# R7FA6T2BD register map
Vendor: Renesas Electronics Corporation; Series: RA6; File version: 1.40.00
CPU: CM33 r0p4, little endian, MPU, FPU, VTOR, 4 interrupt priority bits, 96 interrupts
Registers are 32-bit, read-write, reset 0x0 unless marked. A register's access mark holds for its fields unless they carry their own. Offsets are from the block's base; [hi:lo] are bit positions; {n}, {i} and the like mark numbered series; 'fields as' and 'values as' point back to an identical list.

## CANFD — CANFD Module Control
Base 0x400B0000
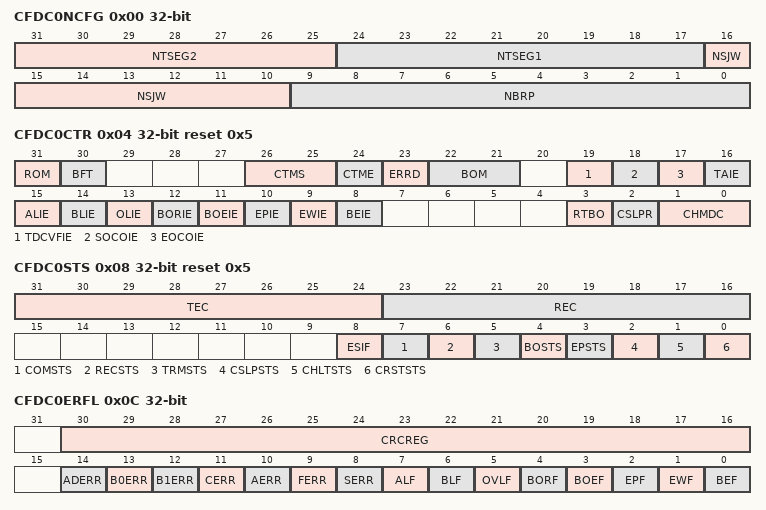
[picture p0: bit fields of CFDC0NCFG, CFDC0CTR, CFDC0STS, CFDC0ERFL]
0x00 CFDC0NCFG — Channel 0 Nominal Bitrate Configuration Register
  [31:25] NTSEG2 — Timing Segment 2
  [24:17] NTSEG1 — Timing Segment 1
  [16:10] NSJW — Resynchronization Jump Width
  [9:0] NBRP — Channel Nominal Baud Rate Prescaler
0x04 CFDC0CTR reset 0x5 — Channel 0 Control Register
  [31] ROM — Restricted Operation Mode
  [30] BFT — Bit Flip Test
  [26:25] CTMS — Channel Test Mode Select
  [24] CTME — Channel Test Mode Enable
  [23] ERRD — Channel Error Display
  [22:21] BOM — Channel Bus,Off Mode
  [19] TDCVFIE — Transceiver Delay Compensation Violation Interrupt Enable
  [18] SOCOIE — Successful Occurrence Counter Overflow Interrupt Enable
  [17] EOCOIE — Error Occurrence Counter Overflow Interrupt Enable
  [16] TAIE — Transmission Abort Interrupt Enable
  [15] ALIE — Arbitration Lost Interrupt Enable
  [14] BLIE — Bus Lock Interrupt Enable
  [13] OLIE — Overload Interrupt Enable
  [12] BORIE — Bus,Off Recovery Interrupt Enable
  [11] BOEIE — Bus,Off Entry Interrupt Enable
  [10] EPIE — Error Passive Interrupt Enable
  [9] EWIE — Error Warning Interrupt Enable
  [8] BEIE — Bus Error Interrupt Enable
  [3] RTBO — Return from Bus,Off
  [2] CSLPR — Channel Sleep Request
  [1:0] CHMDC — Channel Mode Control
0x08 CFDC0STS reset 0x5 — Channel 0 Status Register
  [31:24] TEC ro — Transmission Error Count
  [23:16] REC ro — Reception Error Count
  [8] ESIF — Error State Indication Flag
  [7] COMSTS ro — Channel Communication Status
  [6] RECSTS ro — Channel Receive Status
  [5] TRMSTS ro — Channel Transmit Status
  [4] BOSTS ro — Channel Bus,Off Status
  [3] EPSTS ro — Channel Error Passive Status
  [2] CSLPSTS ro — Channel Sleep Status
  [1] CHLTSTS ro — Channel Halt Status
  [0] CRSTSTS ro — Channel Reset Status
0x0C CFDC0ERFL — Channel 0 Error Flag Register
  [30:16] CRCREG ro — CRC Register value
  [14] ADERR — Acknowledge Delimiter Error
  [13] B0ERR — Bit 0 Error
  [12] B1ERR — Bit 1 Error
  [11] CERR — CRC Error
  [10] AERR — Acknowledge Error
  [9] FERR — Form Error
  [8] SERR — Stuff Error
  [7] ALF — Arbitration Lost Flag
  [6] BLF — Bus Lock Flag
  [5] OVLF — Overload Flag
  [4] BORF — Bus,Off Recovery Flag
  [3] BOEF — Bus,Off Entry Flag
  [2] EPF — Error Passive Flag
  [1] EWF — Error Warning Flag
  [0] BEF — Bus Error Flag
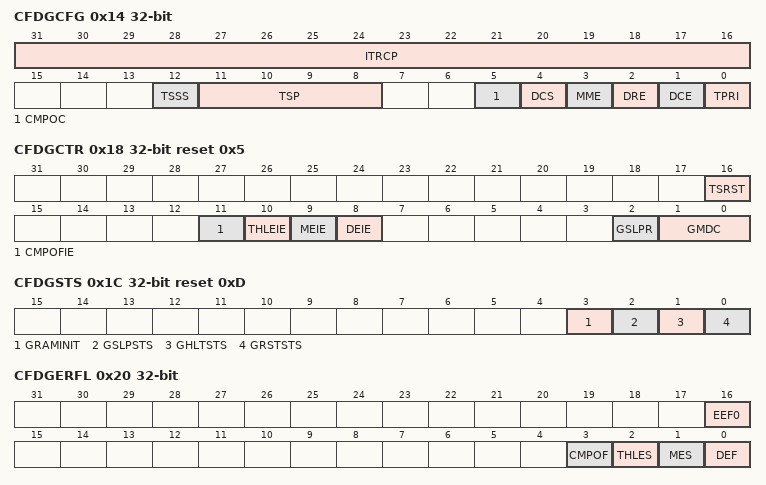
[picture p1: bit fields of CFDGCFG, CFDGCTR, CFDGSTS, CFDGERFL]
0x14 CFDGCFG — Global Configuration Register
  [31:16] ITRCP — Interval Timer Reference Clock Prescaler
  [12] TSSS — Timestamp Source Select
  [11:8] TSP — Timestamp Prescaler
  [5] CMPOC — CANFD Message Payload Overflow Configuration
  [4] DCS — Data Link Controller Clock Select
  [3] MME — Mirror Mode Enable
  [2] DRE — DLC Replacement Enable
  [1] DCE — DLC Check Enable
  [0] TPRI — Transmission Priority
0x18 CFDGCTR reset 0x5 — Global Control Register
  [16] TSRST — Timestamp Reset
  [11] CMPOFIE — CANFD Message Payload Overflow Flag Interrupt Enable
  [10] THLEIE — TX History List Entry Lost Interrupt Enable
  [9] MEIE — Message Lost Error Interrupt Enable
  [8] DEIE — DLC Check Interrupt Enable
  [2] GSLPR — Global Sleep Request
  [1:0] GMDC — Global Mode Control
0x1C CFDGSTS ro reset 0xD — Global Status Register
  [3] GRAMINIT — Global RAM Initialization
  [2] GSLPSTS — Global Sleep Status
  [1] GHLTSTS — Global Halt Status
  [0] GRSTSTS — Global Reset Status
0x20 CFDGERFL — Global Error Flag Register
  [16] EEF0 — ECC Error Flag
  [3] CMPOF — CANFD Message Payload Overflow Flag
  [2] THLES ro — TX History List Entry Lost Error Status
  [1] MES ro — Message Lost Error Status
  [0] DEF — DLC Error Flag
0x24 CFDGTSC ro — Global Timestamp Counter Register
  [15:0] TS — Timestamp value
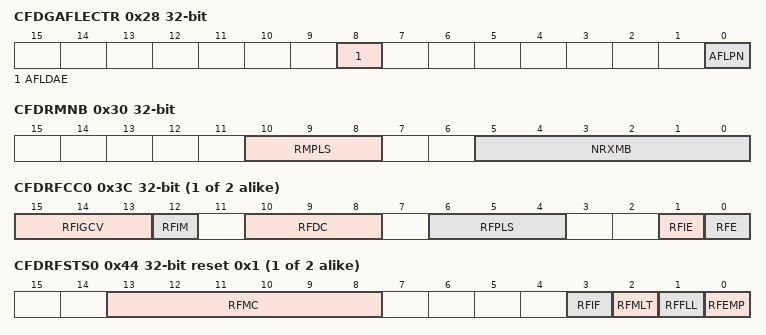
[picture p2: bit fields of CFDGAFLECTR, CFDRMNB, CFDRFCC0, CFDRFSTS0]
0x28 CFDGAFLECTR — Global Acceptance Filter List Entry Control Register
  [8] AFLDAE — Acceptance Filter List Data Access Enable
  [0] AFLPN — Acceptance Filter List Page Number
0x2C CFDGAFLCFG — Global Acceptance Filter List Configuration Register
  [21:16] RNC0 — Rule Number
0x30 CFDRMNB — RX Message Buffer Number Register
  [10:8] RMPLS — Reception Message Buffer Payload Data Size
  [5:0] NRXMB — Number of RX Message Buffers
0x34 CFDRMND — RX Message Buffer New Data Register
  [31:0] RMNS — RX Message Buffer New Data Status
0x38 CFDRMIEC — RX Message Buffer Interrupt Enable Configuration Register
  [31:0] RMIEg — RX Message Buffer Interrupt Enable
{0x3C+4i} CFDRFCC{i} (i=0..1) — RX FIFO Configuration/Control Registers {i}
  [15:13] RFIGCV — RX FIFO Interrupt Generation Counter Value
  [12] RFIM — RX FIFO Interrupt Mode
  [10:8] RFDC — RX FIFO Depth Configuration
  [6:4] RFPLS — Rx FIFO Payload Data Size Configuration
  [1] RFIE — RX FIFO Interrupt Enable
  [0] RFE — RX FIFO Enable
{0x44+4i} CFDRFSTS{i} (i=0..1) reset 0x1 — RX FIFO Status Registers {i}
  [13:8] RFMC ro — RX FIFO Message Count
  [3] RFIF — RX FIFO Interrupt Flag
  [2] RFMLT — RX FIFO Message Lost
  [1] RFFLL ro — RX FIFO Full
  [0] RFEMP ro — RX FIFO Empty
{0x4C+4i} CFDRFPCTR{i} (i=0..1) wo — RX FIFO Pointer Control Registers {i}
  [7:0] RFPC — RX FIFO Pointer Control
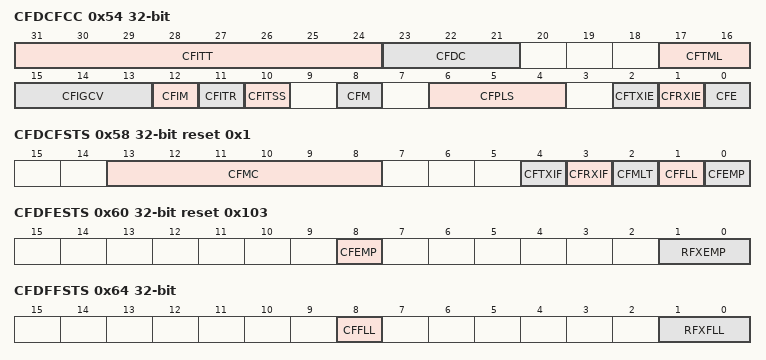
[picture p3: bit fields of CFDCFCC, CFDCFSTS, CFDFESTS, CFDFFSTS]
0x54 CFDCFCC — Common FIFO Configuration/Control Register
  [31:24] CFITT — Common FIFO Interval Transmission Time
  [23:21] CFDC — Common FIFO Depth Configuration
  [17:16] CFTML — Common FIFO TX Message Buffer Link
  [15:13] CFIGCV — Common FIFO Interrupt Generation Counter Value
  [12] CFIM — Common FIFO Interrupt Mode
  [11] CFITR — Common FIFO Interval Timer Resolution
  [10] CFITSS — Common FIFO Interval Timer Source Select
  [8] CFM — Common FIFO Mode
  [6:4] CFPLS — Common FIFO Payload Data Size Configuration
  [2] CFTXIE — Common FIFO TX Interrupt Enable
  [1] CFRXIE — Common FIFO RX Interrupt Enable
  [0] CFE — Common FIFO Enable
0x58 CFDCFSTS reset 0x1 — Common FIFO Status Register
  [13:8] CFMC ro — Common FIFO Message Count
  [4] CFTXIF — Common TX FIFO Interrupt Flag
  [3] CFRXIF — Common RX FIFO Interrupt Flag
  [2] CFMLT — Common FIFO Message Lost
  [1] CFFLL ro — Common FIFO Full
  [0] CFEMP ro — Common FIFO Empty
0x5C CFDCFPCTR wo — Common FIFO Pointer Control Register
  [7:0] CFPC — Common FIFO Pointer Control
0x60 CFDFESTS ro reset 0x103 — FIFO Empty Status Register
  [8] CFEMP — Common FIFO Empty Status
  [1:0] RFXEMP — RX FIFO Empty Status
0x64 CFDFFSTS ro — FIFO Full Status Register
  [8] CFFLL — Common FIF0 Full Status
  [1:0] RFXFLL — RX FIF0 Full Status
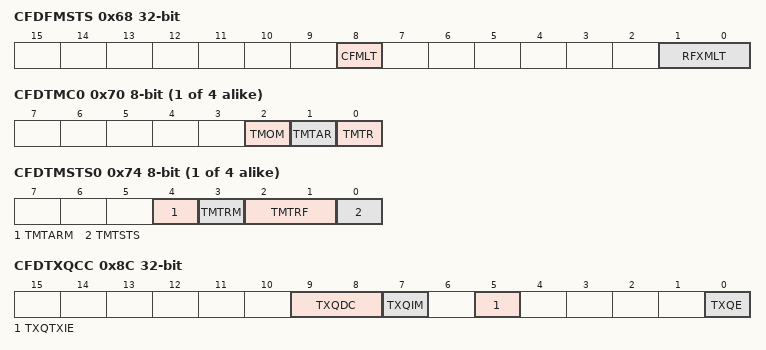
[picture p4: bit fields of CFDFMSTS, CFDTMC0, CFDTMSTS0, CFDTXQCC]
0x68 CFDFMSTS ro — FIFO Message Lost Status Register
  [8] CFMLT — Common FIFO Message Lost Status
  [1:0] RFXMLT — RX FIFO Message Lost Status
0x6C CFDRFISTS ro — RX FIFO Interrupt Flag Status Register
  [1:0] RFXIF — RX FIFO[x] Interrupt Flag Status
{0x70+i} CFDTMC{i} (i=0..3) 8-bit — TX Message Buffer Control Registers {i}
  [2] TMOM — TX Message Buffer One,shot Mode
  [1] TMTAR — TX Message Buffer Transmission Abort Request
  [0] TMTR — TX Message Buffer Transmission Request
{0x74+i} CFDTMSTS{i} (i=0..3) 8-bit — TX Message Buffer Status Registers {i}
  [4] TMTARM ro — TX Message Buffer Transmission Abort Request Mirrored
  [3] TMTRM ro — TX Message Buffer Transmission Request Mirrored
  [2:1] TMTRF — TX Message Buffer Transmission Result Flag
  [0] TMTSTS ro — TX Message Buffer Transmission Status
0x78 CFDTMTRSTS ro — TX Message Buffer Transmission Request Status Register
  [3:0] CFDTMTRSTS — TX Message Buffer Transmission Request Status
0x7C CFDTMTARSTS ro — TX Message Buffer Transmission Abort Request Status Register
  [3:0] CFDTMTARSTS — TX Message Buffer Transmission Abort Request Status
0x80 CFDTMTCSTS ro — TX Message Buffer Transmission Completion Status Register
  [3:0] CFDTMTCSTS — TX Message Buffer Transmission Completion Status
0x84 CFDTMTASTS ro — TX Message Buffer Transmission Abort Status Register
  [3:0] CFDTMTASTS — TX Message Buffer Transmission Abort Status
0x88 CFDTMIEC — TX Message Buffer Interrupt Enable Configuration Register
  [3:0] TMIEg — TX Message Buffer Interrupt Enable
0x8C CFDTXQCC — TX Queue Configuration/Control Register
  [9:8] TXQDC — TX Queue Depth Configuration
  [7] TXQIM — TX Queue Interrupt Mode
  [5] TXQTXIE — TX Queue TX Interrupt Enable
  [0] TXQE — TX Queue Enable
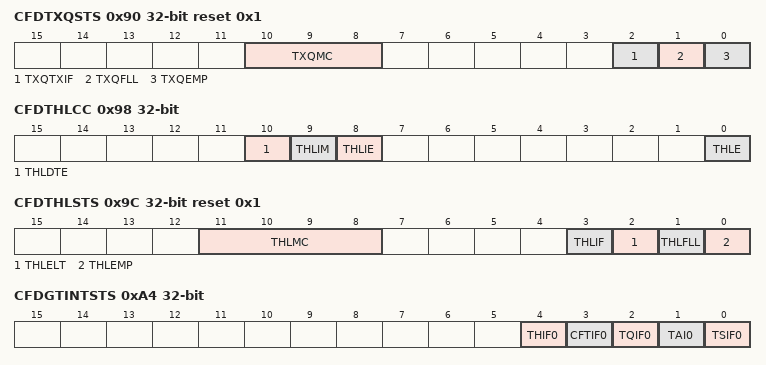
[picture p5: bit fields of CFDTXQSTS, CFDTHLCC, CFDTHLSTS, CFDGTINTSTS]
0x90 CFDTXQSTS reset 0x1 — TX Queue Status Register
  [10:8] TXQMC ro — TX Queue Message Count
  [2] TXQTXIF — TX Queue TX Interrupt Flag
  [1] TXQFLL ro — TX Queue Full
  [0] TXQEMP ro — TX Queue Empty
0x94 CFDTXQPCTR wo — TX Queue Pointer Control Register
  [7:0] TXQPC — TX Queue Pointer Control
0x98 CFDTHLCC — TX History List Configuration/Control Register
  [10] THLDTE — TX History List Dedicated TX Enable
  [9] THLIM — TX History List Interrupt Mode
  [8] THLIE — TX History List Interrupt Enable
  [0] THLE — TX History List Enable
0x9C CFDTHLSTS reset 0x1 — TX History List Status Register
  [11:8] THLMC ro — TX History List Message Count
  [3] THLIF — TX History List Interrupt Flag
  [2] THLELT — TX History List Entry Lost
  [1] THLFLL ro — TX History List Full
  [0] THLEMP ro — TX History List Empty
0xA0 CFDTHLPCTR wo — TX History List Pointer Control Register
  [7:0] THLPC — TX History List Pointer Control
0xA4 CFDGTINTSTS ro — Global TX Interrupt Status Register
  [4] THIF0 — TX History List Interrupt
  [3] CFTIF0 — COM FIFO TX Mode Interrupt Flag
  [2] TQIF0 — TX Queue Interrupt Flag
  [1] TAI0 — TX Abort Interrupt Flag
  [0] TSIF0 — TX Successful Interrupt Flag
0xA8 CFDGTSTCFG — Global Test Configuration Register
  [19:16] RTMPS — RAM Test Mode Page Select
0xAC CFDGTSTCTR — Global Test Control Register
  [2] RTME — RAM Test Mode Enable
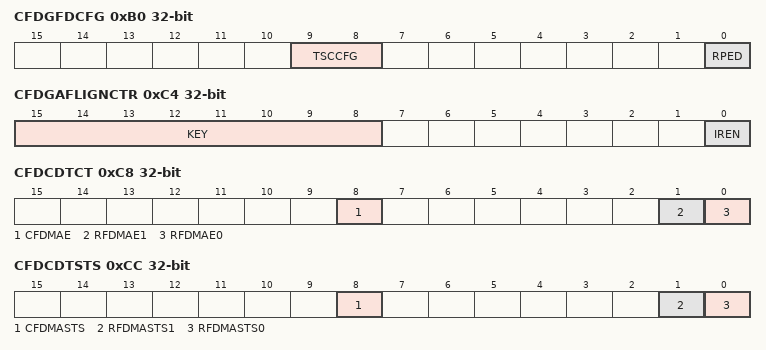
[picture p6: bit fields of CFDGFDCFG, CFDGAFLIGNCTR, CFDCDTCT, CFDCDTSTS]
0xB0 CFDGFDCFG — Global FD Configuration Register
  [9:8] TSCCFG — Timestamp Capture Configuration
  [0] RPED — RES Bit Protocol Exception Disable
0xB8 CFDGLOCKK wo — Global Lock Key Register
  [15:0] LOCK — Lock Key
0xC0 CFDGAFLIGNENT — Global AFL Ignore Entry Register
  [4:0] IRN — Ignore Rule Number
0xC4 CFDGAFLIGNCTR — Global AFL Ignore Control Register
  [15:8] KEY wo — Key Code
  [0] IREN — Ignore Rule Enable
0xC8 CFDCDTCT — DMA Transfer Control Register
  [8] CFDMAE — DMA Transfer Enable for Common FIFO 0
  [1] RFDMAE1 — DMA Transfer Enable for RXFIFO 1
  [0] RFDMAE0 — DMA Transfer Enable for RXFIFO 0
0xCC CFDCDTSTS ro — DMA Transfer Status Register
  [8] CFDMASTS — DMA Transfer Status only for Common FIFO
  [1] RFDMASTS1 — DMA Transfer Status for RX FIFO 1
  [0] RFDMASTS0 — DMA Transfer Status for RX FIFO 0
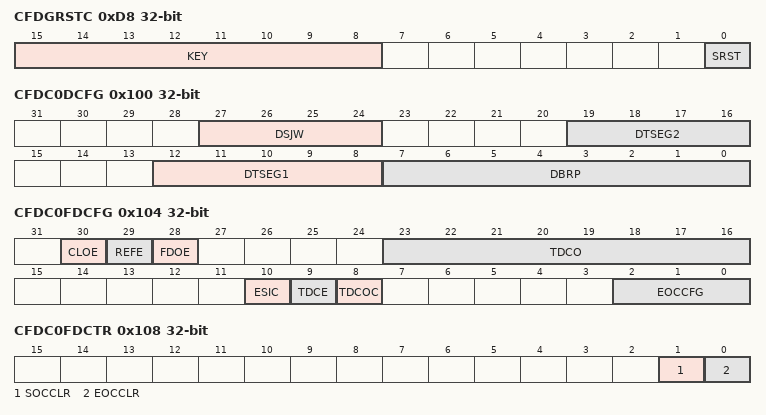
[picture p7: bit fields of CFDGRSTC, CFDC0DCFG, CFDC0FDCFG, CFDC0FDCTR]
0xD8 CFDGRSTC — Global SW reset Register
  [15:8] KEY wo — Key Code
  [0] SRST — SW Reset
0x100 CFDC0DCFG — Channel 0 Data Bitrate Configuration Register
  [27:24] DSJW — Resynchronization Jump Width
  [19:16] DTSEG2 — Timing Segment 2
  [12:8] DTSEG1 — Timing Segment 1
  [7:0] DBRP — Channel Data Baud Rate Prescaler
0x104 CFDC0FDCFG (reset mask 0xBFFFFFFF) — Channel 0 CANFD Configuration Register
  [30] CLOE — Classical CAN Enable
  [29] REFE — RX Edge Filter Enable
  [28] FDOE — FD,Only Enable
  [23:16] TDCO — Transceiver Delay Compensation Offset
  [10] ESIC — Error State Indication Configuration
  [9] TDCE — Transceiver Delay Compensation Enable
  [8] TDCOC — Transceiver Delay Compensation Offset Configuration
  [2:0] EOCCFG — Error Occurrence Counter Configuration
0x108 CFDC0FDCTR — Channel 0 CANFD Control Register
  [1] SOCCLR — Successful Occurrence Counter Clear
  [0] EOCCLR — Error Occurrence Counter Clear
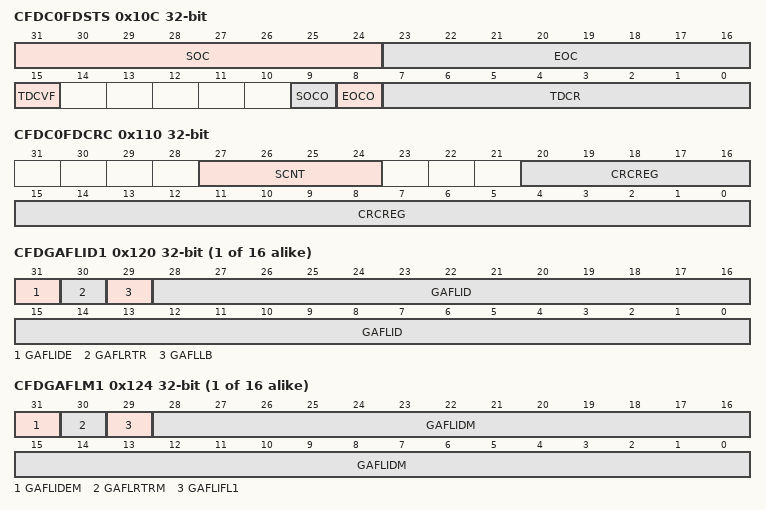
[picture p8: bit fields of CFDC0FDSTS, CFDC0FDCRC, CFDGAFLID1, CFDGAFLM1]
0x10C CFDC0FDSTS — Channel 0 CANFD Status Register
  [31:24] SOC ro — Successful occurrence counter
  [23:16] EOC ro — Error Occurrence Counter
  [15] TDCVF — Transceiver Delay Compensation Violation Flag
  [9] SOCO — Successful Occurrence Counter Overflow
  [8] EOCO — Error Occurrence Counter Overflow
  [7:0] TDCR ro — Transceiver Delay Compensation Result
0x110 CFDC0FDCRC — Channel 0 CANFD CRC Register
  [27:24] SCNT ro — Stuff bit count
  [20:0] CRCREG ro — CRC Register value
{0x110+0x10*i} CFDGAFLID{i} (i=1..16) — Global Acceptance Filter List ID Registers
  [31] GAFLIDE — Global Acceptance Filter List Entry IDE Field
  [30] GAFLRTR — Global Acceptance Filter List Entry RTR Field
  [29] GAFLLB — Global Acceptance Filter List Entry Loopback Configuration
  [28:0] GAFLID — Global Acceptance Filter List Entry ID Field
{0x114+0x10*i} CFDGAFLM{i} (i=1..16) — Global Acceptance Filter List Mask Registers
  [31] GAFLIDEM — Global Acceptance Filter List IDE Mask
  [30] GAFLRTRM — Global Acceptance Filter List Entry RTR Mask
  [29] GAFLIFL1 — Global Acceptance Filter List Information Label 1
  [28:0] GAFLIDM — Global Acceptance Filter List ID Mask Field
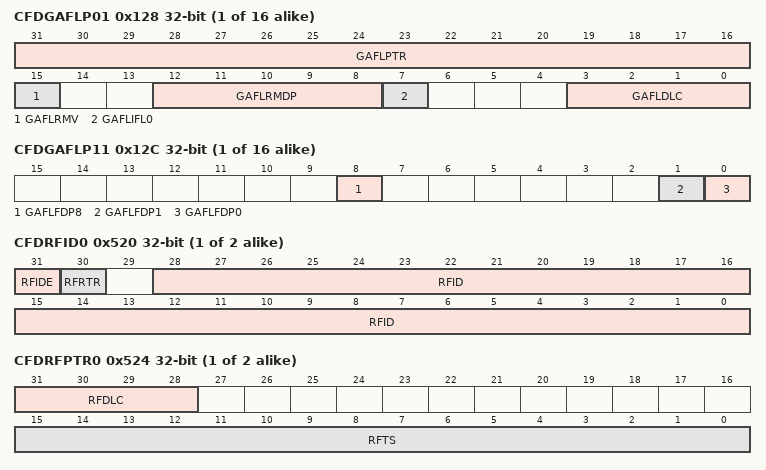
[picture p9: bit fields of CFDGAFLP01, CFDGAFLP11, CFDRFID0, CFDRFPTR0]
{0x118+0x10*i} CFDGAFLP0{i} (i=1..16) — Global Acceptance Filter List Pointer 0 Registers
  [31:16] GAFLPTR — Global Acceptance Filter List Pointer
  [15] GAFLRMV — Global Acceptance Filter List RX Message Buffer Valid
  [12:8] GAFLRMDP — Global Acceptance Filter List RX Message Buffer Direction Pointer
  [7] GAFLIFL0 — Global Acceptance Filter List Information Label 0
  [3:0] GAFLDLC — Global Acceptance Filter List DLC Field
{0x11C+0x10*i} CFDGAFLP1{i} (i=1..16) — Global Acceptance Filter List Pointer 1 Registers
  [8] GAFLFDP8 — Global Acceptance Filter List FIFO Direction Pointer
  [1] GAFLFDP1 — Global Acceptance Filter List FIFO Direction Pointer
  [0] GAFLFDP0 — Global Acceptance Filter List FIFO Direction Pointer
{0x280+4i} CFDRPGACC{i} (i=0..63) — RAM Test Page Access Registers {i}
  [31:0] RDTA — RAM Data Test Access
{0x520+0x4C*i} CFDRFID{i} (i=0..1) ro — RX FIFO Access ID Register {i}
  [31] RFIDE — RX FIFO Buffer IDE bit
  [30] RFRTR — RX FIFO Buffer RTR bit
  [28:0] RFID — RX FIFO Buffer ID Field
{0x524+0x4C*i} CFDRFPTR{i} (i=0..1) ro — RX FIFO Access Pointer Register {i}
  [31:28] RFDLC — RX FIFO Buffer DLC Field
  [15:0] RFTS — RX FIFO Timestamp Value
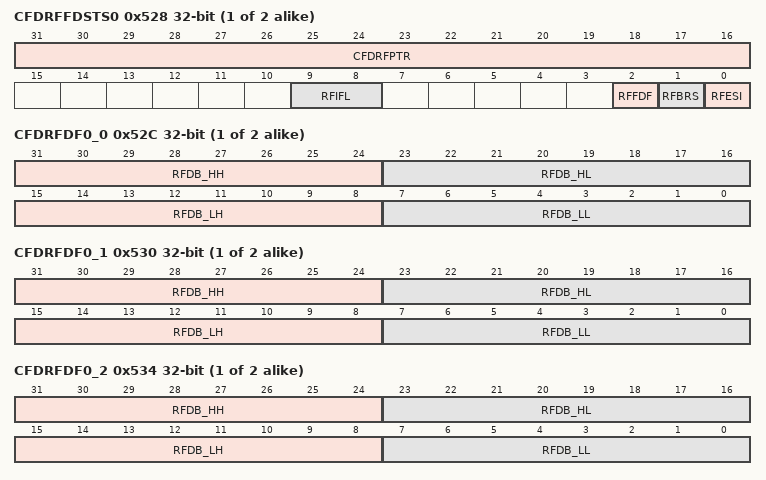
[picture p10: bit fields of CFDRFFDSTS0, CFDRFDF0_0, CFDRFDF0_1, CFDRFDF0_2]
{0x528+0x4C*i} CFDRFFDSTS{i} (i=0..1) ro — RX FIFO Access CANFD Status Register {i}
  [31:16] CFDRFPTR — RX FIFO Buffer Pointer Field
  [9:8] RFIFL — RX FIFO Buffer Information Label Field
  [2] RFFDF — CAN FD Format bit
  [1] RFBRS — Bit Rate Switch bit
  [0] RFESI — Error State Indicator bit
{0x52C+0x4C*i} CFDRFDF{i}_0 (i=0..1) ro — RX FIFO Access Data Field 0 Register {i}
  [31:24] RFDB_HH — RX FIFO Buffer Data Byte ((p × 4) + 3)
  [23:16] RFDB_HL — RX FIFO Buffer Data Byte ((p × 4) + 2)
  [15:8] RFDB_LH — RX FIFO Buffer Data Byte ((p × 4) + 1)
  [7:0] RFDB_LL — RX FIFO Buffer Data Byte (p × 4)
{0x530+0x4C*i} CFDRFDF{i}_1 (i=0..1) ro — RX FIFO Access Data Field 1 Register {i}
  fields as CFDRFDF0_0
{0x534+0x4C*i} CFDRFDF{i}_2 (i=0..1) ro — RX FIFO Access Data Field 2 Register {i}
  fields as CFDRFDF0_0
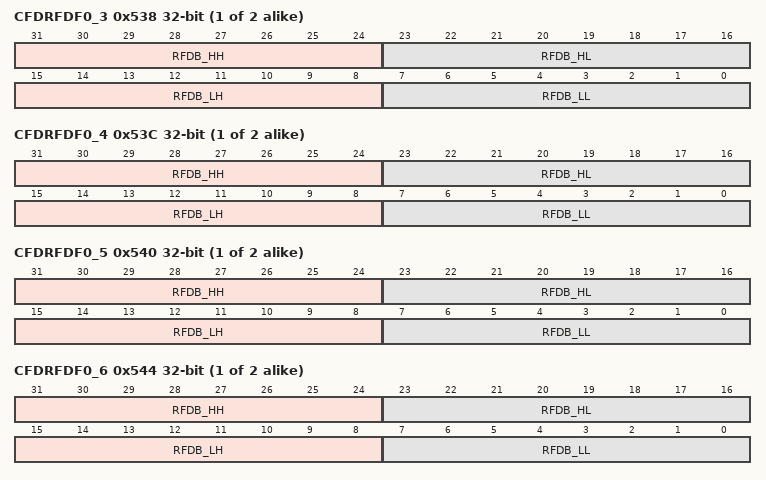
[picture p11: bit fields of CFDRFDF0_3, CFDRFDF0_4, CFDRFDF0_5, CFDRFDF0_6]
{0x538+0x4C*i} CFDRFDF{i}_3 (i=0..1) ro — RX FIFO Access Data Field 3 Register {i}
  fields as CFDRFDF0_0
{0x53C+0x4C*i} CFDRFDF{i}_4 (i=0..1) ro — RX FIFO Access Data Field 4 Register {i}
  fields as CFDRFDF0_0
{0x540+0x4C*i} CFDRFDF{i}_5 (i=0..1) ro — RX FIFO Access Data Field 5 Register {i}
  fields as CFDRFDF0_0
{0x544+0x4C*i} CFDRFDF{i}_6 (i=0..1) ro — RX FIFO Access Data Field 6 Register {i}
  fields as CFDRFDF0_0
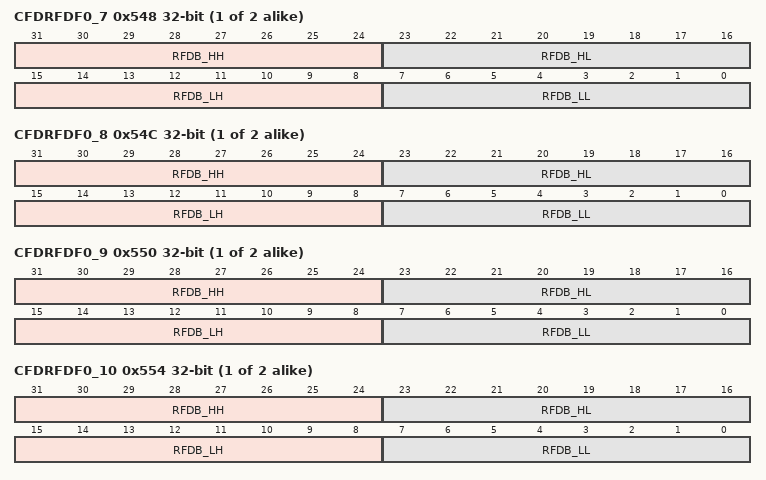
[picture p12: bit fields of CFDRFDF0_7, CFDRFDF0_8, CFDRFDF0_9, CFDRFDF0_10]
{0x548+0x4C*i} CFDRFDF{i}_7 (i=0..1) ro — RX FIFO Access Data Field 7 Register {i}
  fields as CFDRFDF0_0
{0x54C+0x4C*i} CFDRFDF{i}_8 (i=0..1) ro — RX FIFO Access Data Field 8 Register {i}
  fields as CFDRFDF0_0
{0x550+0x4C*i} CFDRFDF{i}_9 (i=0..1) ro — RX FIFO Access Data Field 9 Register {i}
  fields as CFDRFDF0_0
{0x554+0x4C*i} CFDRFDF{i}_10 (i=0..1) ro — RX FIFO Access Data Field 10 Register {i}
  fields as CFDRFDF0_0
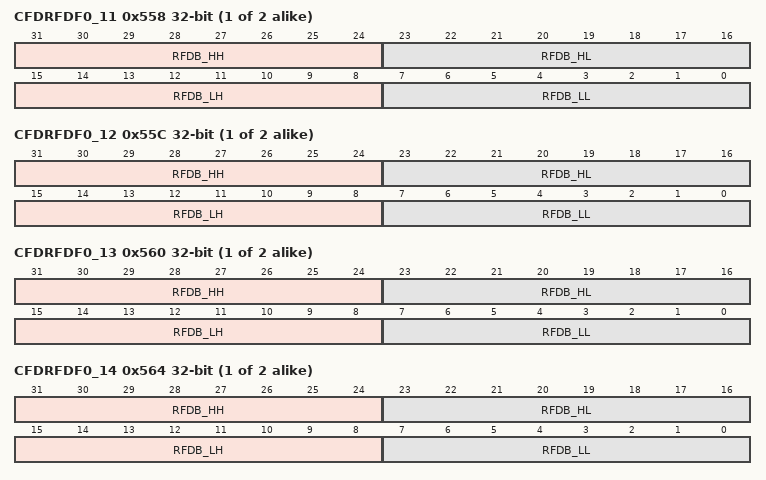
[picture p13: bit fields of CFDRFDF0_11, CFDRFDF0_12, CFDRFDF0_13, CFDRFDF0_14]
{0x558+0x4C*i} CFDRFDF{i}_11 (i=0..1) ro — RX FIFO Access Data Field 11 Register {i}
  fields as CFDRFDF0_0
{0x55C+0x4C*i} CFDRFDF{i}_12 (i=0..1) ro — RX FIFO Access Data Field 12 Register {i}
  fields as CFDRFDF0_0
{0x560+0x4C*i} CFDRFDF{i}_13 (i=0..1) ro — RX FIFO Access Data Field 13 Register {i}
  fields as CFDRFDF0_0
{0x564+0x4C*i} CFDRFDF{i}_14 (i=0..1) ro — RX FIFO Access Data Field 14 Register {i}
  fields as CFDRFDF0_0
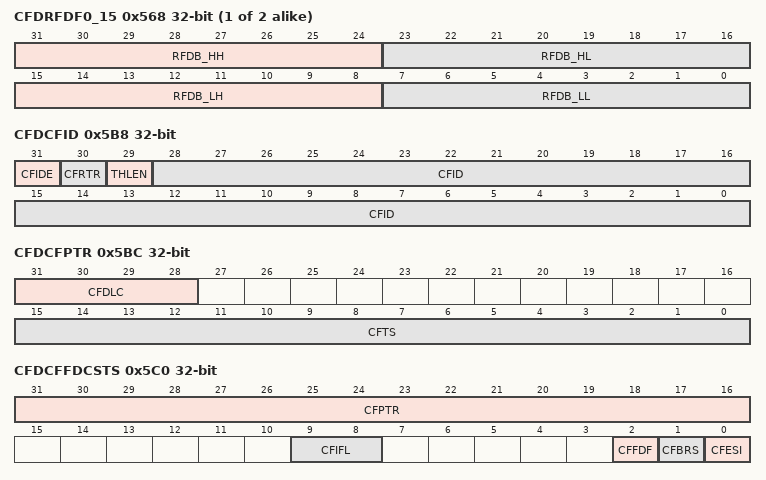
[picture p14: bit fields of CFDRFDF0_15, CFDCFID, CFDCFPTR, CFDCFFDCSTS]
{0x568+0x4C*i} CFDRFDF{i}_15 (i=0..1) ro — RX FIFO Access Data Field 15 Register {i}
  fields as CFDRFDF0_0
0x5B8 CFDCFID — Common FIFO Access ID Register
  [31] CFIDE — Common FIFO Buffer IDE Bit
  [30] CFRTR — Common FIFO Buffer RTR Bit
  [29] THLEN — THL Entry enable
  [28:0] CFID — Common FIFO Buffer ID Field
0x5BC CFDCFPTR — Common FIFO Access Pointer Register
  [31:28] CFDLC — Common FIFO Buffer DLC Field
  [15:0] CFTS — Common FIFO Timestamp Value
0x5C0 CFDCFFDCSTS — Common FIFO Access CANFD Control/Status Register
  [31:16] CFPTR — Common FIFO Buffer Pointer Field
  [9:8] CFIFL — COMMON FIFO Buffer Information Label Field
  [2] CFFDF — CAN FD Format bit
  [1] CFBRS — Bit Rate Switch bit
  [0] CFESI — Error State Indicator bit
{0x5C4+4i} CFDCFDF{i} (i=0..15) — Common FIFO Access Data Field {i} Registers
  [31:24] CFDB_HH — Common FIFO Buffer Data Bytes ((p × 4) + 3)
  [23:16] CFDB_HL — Common FIFO Buffer Data Bytes ((p × 4) + 2)
  [15:8] CFDB_LH — Common FIFO Buffer Data Bytes ((p × 4) + 1)
  [7:0] CFDB_LL — Common FIFO Buffer Data Bytes (p × 4)
{0x604+0x4C*i} CFDTMID{i} (i=0..3) — TX Message Buffer ID Registers
  [31] TMIDE — TX Message Buffer IDE bit
  [30] TMRTR — TX Message Buffer RTR bit
  [29] THLEN — Tx History List Entry
  [28:0] TMID — TX Message Buffer ID Field
{0x608+0x4C*i} CFDTMPTR{i} (i=0..3) — TX Message Buffer Pointer Register
  [31:28] TMDLC — TX Message Buffer DLC Field
{0x60C+0x4C*i} CFDTMFDCTR{i} (i=0..3) — TX Message Buffer CANFD Control Register
  [31:16] TMPTR — TX Message Buffer Pointer Field
  [9:8] TMIFL — TX Message Buffer Information Label Field
  [2] TMFDF — CAN FD Format bit
  [1] TMBRS — Bit Rate Switch bit
  [0] TMESI — Error State Indicator bit
{0x610+0x4C*i} CFDTMDF{i}_0 (i=0..3) — TX Message Buffer Data Field Register
  [31:24] TMDB_HH — TX Message Buffer Data Byte ((p × 4) + 3)
  [23:16] TMDB_HL — TX Message Buffer Data Byte ((p × 4) + 2)
  [15:8] TMDB_LH — TX Message Buffer Data Byte ((p × 4) + 1)
  [7:0] TMDB_LL — TX Message Buffer Data Byte ((p × 4)
{0x614+0x4C*i} CFDTMDF{i}_1 (i=0..3) — TX Message Buffer Data Field Register
  fields as CFDTMDF0_0
{0x618+0x4C*i} CFDTMDF{i}_2 (i=0..3) — TX Message Buffer Data Field Register
  fields as CFDTMDF0_0
{0x61C+0x4C*i} CFDTMDF{i}_3 (i=0..3) — TX Message Buffer Data Field Register
  fields as CFDTMDF0_0
{0x620+0x4C*i} CFDTMDF{i}_4 (i=0..3) — TX Message Buffer Data Field Register
  fields as CFDTMDF0_0
{0x624+0x4C*i} CFDTMDF{i}_5 (i=0..3) — TX Message Buffer Data Field Register
  fields as CFDTMDF0_0
{0x628+0x4C*i} CFDTMDF{i}_6 (i=0..3) — TX Message Buffer Data Field Register
  fields as CFDTMDF0_0
{0x62C+0x4C*i} CFDTMDF{i}_7 (i=0..3) — TX Message Buffer Data Field Register
  fields as CFDTMDF0_0
{0x630+0x4C*i} CFDTMDF{i}_8 (i=0..3) — TX Message Buffer Data Field Register
  fields as CFDTMDF0_0
{0x634+0x4C*i} CFDTMDF{i}_9 (i=0..3) — TX Message Buffer Data Field Register
  fields as CFDTMDF0_0
{0x638+0x4C*i} CFDTMDF{i}_10 (i=0..3) — TX Message Buffer Data Field Register
  fields as CFDTMDF0_0
{0x63C+0x4C*i} CFDTMDF{i}_11 (i=0..3) — TX Message Buffer Data Field Register
  fields as CFDTMDF0_0
{0x640+0x4C*i} CFDTMDF{i}_12 (i=0..3) — TX Message Buffer Data Field Register
  fields as CFDTMDF0_0
{0x644+0x4C*i} CFDTMDF{i}_13 (i=0..3) — TX Message Buffer Data Field Register
  fields as CFDTMDF0_0
{0x648+0x4C*i} CFDTMDF{i}_14 (i=0..3) — TX Message Buffer Data Field Register
  fields as CFDTMDF0_0
{0x64C+0x4C*i} CFDTMDF{i}_15 (i=0..3) — TX Message Buffer Data Field Register
  fields as CFDTMDF0_0
0x740 CFDTHLACC0 ro — TX History List Access Register 0
  [31:16] TMTS — Transmit Timestamp
  [4:3] BN — Buffer Number
  [2:0] BT — Buffer Type
0x744 CFDTHLACC1 ro — TX History List Access Register 1
  [17:16] TIFL — Transmit Information Label
  [15:0] TID — Transmit ID
{0x920+0x4C*i} CFDRMID{i} (i=0..7) ro — RX Message Buffer ID Registers
  [31] RMIDE — RX Message Buffer IDE Bit
  [30] RMRTR — RX Message Buffer RTR Bit
  [28:0] RMID — RX Message Buffer ID Field
{0x924+0x4C*i} CFDRMPTR{i} (i=0..7) ro — RX Message Buffer Pointer Registers
  [31:28] RMDLC — RX Message Buffer DLC Field
  [15:0] RMTS — RX Message Buffer Timestamp Field
{0x928+0x4C*i} CFDRMFDSTS{i} (i=0..7) ro — RX Message Buffer CANFD Status Registers
  [31:16] RMPTR — RX Message Buffer Pointer Field
  [9:8] RMIFL — RX Message Buffer Information Label Field
  [2] RMFDF — CAN FD Format bit
  [1] RMBRS — Bit Rate Switch bit
  [0] RMESI — Error State Indicator bit
{0x92C+0x4C*i} CFDRMDF{i}_0 (i=0..7) ro — RX Message Buffer Data Field 0 Registers
  [31:24] RMDB_HH — RX Message Buffer Data Byte ((p × 4) + 3)
  [23:16] RMDB_HL — RX Message Buffer Data Byte ((p × 4) + 2)
  [15:8] RMDB_LH — RX Message Buffer Data Byte ((p × 4) + 1)
  [7:0] RMDB_LL — RX Message Buffer Data Byte (p × 4)
{0x930+0x4C*i} CFDRMDF{i}_1 (i=0..7) ro — RX Message Buffer Data Field 1 Registers
  fields as CFDRMDF0_0
{0x934+0x4C*i} CFDRMDF{i}_2 (i=0..7) ro — RX Message Buffer Data Field 2 Registers
  fields as CFDRMDF0_0
{0x938+0x4C*i} CFDRMDF{i}_3 (i=0..7) ro — RX Message Buffer Data Field 3 Registers
  fields as CFDRMDF0_0
{0x93C+0x4C*i} CFDRMDF{i}_4 (i=0..7) ro — RX Message Buffer Data Field 4 Registers
  fields as CFDRMDF0_0
{0x940+0x4C*i} CFDRMDF{i}_5 (i=0..7) ro — RX Message Buffer Data Field 5 Registers
  fields as CFDRMDF0_0
{0x944+0x4C*i} CFDRMDF{i}_6 (i=0..7) ro — RX Message Buffer Data Field 6 Registers
  fields as CFDRMDF0_0
{0x948+0x4C*i} CFDRMDF{i}_7 (i=0..7) ro — RX Message Buffer Data Field 7 Registers
  fields as CFDRMDF0_0
{0x94C+0x4C*i} CFDRMDF{i}_8 (i=0..7) ro — RX Message Buffer Data Field 8 Registers
  fields as CFDRMDF0_0
{0x950+0x4C*i} CFDRMDF{i}_9 (i=0..7) ro — RX Message Buffer Data Field 9 Registers
  fields as CFDRMDF0_0
{0x954+0x4C*i} CFDRMDF{i}_10 (i=0..7) ro — RX Message Buffer Data Field 10 Registers
  fields as CFDRMDF0_0
{0x958+0x4C*i} CFDRMDF{i}_11 (i=0..7) ro — RX Message Buffer Data Field 11 Registers
  fields as CFDRMDF0_0
{0x95C+0x4C*i} CFDRMDF{i}_12 (i=0..7) ro — RX Message Buffer Data Field 12 Registers
  fields as CFDRMDF0_0
{0x960+0x4C*i} CFDRMDF{i}_13 (i=0..7) ro — RX Message Buffer Data Field 13 Registers
  fields as CFDRMDF0_0
{0x964+0x4C*i} CFDRMDF{i}_14 (i=0..7) ro — RX Message Buffer Data Field 14 Registers
  fields as CFDRMDF0_0
{0x968+0x4C*i} CFDRMDF{i}_15 (i=0..7) ro — RX Message Buffer Data Field 15 Registers
  fields as CFDRMDF0_0
{0xAC0+0x4C*i} CFDRMID{i}_1 (i=8..15) ro — RX Message Buffer ID Registers
  fields as CFDRMID0
{0xAC4+0x4C*i} CFDRMPTR{i}_1 (i=8..15) ro — RX Message Buffer Pointer Registers
  fields as CFDRMPTR0
{0xAC8+0x4C*i} CFDRMFDSTS{i}_1 (i=8..15) ro — RX Message Buffer CANFD Status Registers
  fields as CFDRMFDSTS0
{0xACC+0x4C*i} CFDRMDF{i}_0_1 (i=8..15) ro — RX Message Buffer Data Field 0 Registers
  fields as CFDRMDF0_0
{0xAD0+0x4C*i} CFDRMDF{i}_1_1 (i=8..15) ro — RX Message Buffer Data Field 1 Registers
  fields as CFDRMDF0_0
{0xAD4+0x4C*i} CFDRMDF{i}_2_1 (i=8..15) ro — RX Message Buffer Data Field 2 Registers
  fields as CFDRMDF0_0
{0xAD8+0x4C*i} CFDRMDF{i}_3_1 (i=8..15) ro — RX Message Buffer Data Field 3 Registers
  fields as CFDRMDF0_0
{0xADC+0x4C*i} CFDRMDF{i}_4_1 (i=8..15) ro — RX Message Buffer Data Field 4 Registers
  fields as CFDRMDF0_0
{0xAE0+0x4C*i} CFDRMDF{i}_5_1 (i=8..15) ro — RX Message Buffer Data Field 5 Registers
  fields as CFDRMDF0_0
{0xAE4+0x4C*i} CFDRMDF{i}_6_1 (i=8..15) ro — RX Message Buffer Data Field 6 Registers
  fields as CFDRMDF0_0
{0xAE8+0x4C*i} CFDRMDF{i}_7_1 (i=8..15) ro — RX Message Buffer Data Field 7 Registers
  fields as CFDRMDF0_0
{0xAEC+0x4C*i} CFDRMDF{i}_8_1 (i=8..15) ro — RX Message Buffer Data Field 8 Registers
  fields as CFDRMDF0_0
{0xAF0+0x4C*i} CFDRMDF{i}_9_1 (i=8..15) ro — RX Message Buffer Data Field 9 Registers
  fields as CFDRMDF0_0
{0xAF4+0x4C*i} CFDRMDF{i}_10_1 (i=8..15) ro — RX Message Buffer Data Field 10 Registers
  fields as CFDRMDF0_0
{0xAF8+0x4C*i} CFDRMDF{i}_11_1 (i=8..15) ro — RX Message Buffer Data Field 11 Registers
  fields as CFDRMDF0_0
{0xAFC+0x4C*i} CFDRMDF{i}_12_1 (i=8..15) ro — RX Message Buffer Data Field 12 Registers
  fields as CFDRMDF0_0
{0xB00+0x4C*i} CFDRMDF{i}_13_1 (i=8..15) ro — RX Message Buffer Data Field 13 Registers
  fields as CFDRMDF0_0
{0xB04+0x4C*i} CFDRMDF{i}_14_1 (i=8..15) ro — RX Message Buffer Data Field 14 Registers
  fields as CFDRMDF0_0
{0xB08+0x4C*i} CFDRMDF{i}_15_1 (i=8..15) ro — RX Message Buffer Data Field 15 Registers
  fields as CFDRMDF0_0
{0xC60+0x4C*i} CFDRMID{i}_2 (i=16..23) ro — RX Message Buffer ID Registers
  fields as CFDRMID0
{0xC64+0x4C*i} CFDRMPTR{i}_2 (i=16..23) ro — RX Message Buffer Pointer Registers
  fields as CFDRMPTR0
{0xC68+0x4C*i} CFDRMFDSTS{i}_2 (i=16..23) ro — RX Message Buffer CANFD Status Registers
  fields as CFDRMFDSTS0
{0xC6C+0x4C*i} CFDRMDF{i}_0_2 (i=16..23) ro — RX Message Buffer Data Field 0 Registers
  fields as CFDRMDF0_0
{0xC70+0x4C*i} CFDRMDF{i}_1_2 (i=16..23) ro — RX Message Buffer Data Field 1 Registers
  fields as CFDRMDF0_0
{0xC74+0x4C*i} CFDRMDF{i}_2_2 (i=16..23) ro — RX Message Buffer Data Field 2 Registers
  fields as CFDRMDF0_0
{0xC78+0x4C*i} CFDRMDF{i}_3_2 (i=16..23) ro — RX Message Buffer Data Field 3 Registers
  fields as CFDRMDF0_0
{0xC7C+0x4C*i} CFDRMDF{i}_4_2 (i=16..23) ro — RX Message Buffer Data Field 4 Registers
  fields as CFDRMDF0_0
{0xC80+0x4C*i} CFDRMDF{i}_5_2 (i=16..23) ro — RX Message Buffer Data Field 5 Registers
  fields as CFDRMDF0_0
{0xC84+0x4C*i} CFDRMDF{i}_6_2 (i=16..23) ro — RX Message Buffer Data Field 6 Registers
  fields as CFDRMDF0_0
{0xC88+0x4C*i} CFDRMDF{i}_7_2 (i=16..23) ro — RX Message Buffer Data Field 7 Registers
  fields as CFDRMDF0_0
{0xC8C+0x4C*i} CFDRMDF{i}_8_2 (i=16..23) ro — RX Message Buffer Data Field 8 Registers
  fields as CFDRMDF0_0
{0xC90+0x4C*i} CFDRMDF{i}_9_2 (i=16..23) ro — RX Message Buffer Data Field 9 Registers
  fields as CFDRMDF0_0
{0xC94+0x4C*i} CFDRMDF{i}_10_2 (i=16..23) ro — RX Message Buffer Data Field 10 Registers
  fields as CFDRMDF0_0
{0xC98+0x4C*i} CFDRMDF{i}_11_2 (i=16..23) ro — RX Message Buffer Data Field 11 Registers
  fields as CFDRMDF0_0
{0xC9C+0x4C*i} CFDRMDF{i}_12_2 (i=16..23) ro — RX Message Buffer Data Field 12 Registers
  fields as CFDRMDF0_0
{0xCA0+0x4C*i} CFDRMDF{i}_13_2 (i=16..23) ro — RX Message Buffer Data Field 13 Registers
  fields as CFDRMDF0_0
{0xCA4+0x4C*i} CFDRMDF{i}_14_2 (i=16..23) ro — RX Message Buffer Data Field 14 Registers
  fields as CFDRMDF0_0
{0xCA8+0x4C*i} CFDRMDF{i}_15_2 (i=16..23) ro — RX Message Buffer Data Field 15 Registers
  fields as CFDRMDF0_0
{0xE00+0x4C*i} CFDRMID{i}_3 (i=24..31) ro — RX Message Buffer ID Registers
  fields as CFDRMID0
{0xE04+0x4C*i} CFDRMPTR{i}_3 (i=24..31) ro — RX Message Buffer Pointer Registers
  fields as CFDRMPTR0
{0xE08+0x4C*i} CFDRMFDSTS{i}_3 (i=24..31) ro — RX Message Buffer CANFD Status Registers
  fields as CFDRMFDSTS0
{0xE0C+0x4C*i} CFDRMDF{i}_0_3 (i=24..31) ro — RX Message Buffer Data Field 0 Registers
  fields as CFDRMDF0_0
{0xE10+0x4C*i} CFDRMDF{i}_1_3 (i=24..31) ro — RX Message Buffer Data Field 1 Registers
  fields as CFDRMDF0_0
{0xE14+0x4C*i} CFDRMDF{i}_2_3 (i=24..31) ro — RX Message Buffer Data Field 2 Registers
  fields as CFDRMDF0_0
{0xE18+0x4C*i} CFDRMDF{i}_3_3 (i=24..31) ro — RX Message Buffer Data Field 3 Registers
  fields as CFDRMDF0_0
{0xE1C+0x4C*i} CFDRMDF{i}_4_3 (i=24..31) ro — RX Message Buffer Data Field 4 Registers
  fields as CFDRMDF0_0
{0xE20+0x4C*i} CFDRMDF{i}_5_3 (i=24..31) ro — RX Message Buffer Data Field 5 Registers
  fields as CFDRMDF0_0
{0xE24+0x4C*i} CFDRMDF{i}_6_3 (i=24..31) ro — RX Message Buffer Data Field 6 Registers
  fields as CFDRMDF0_0
{0xE28+0x4C*i} CFDRMDF{i}_7_3 (i=24..31) ro — RX Message Buffer Data Field 7 Registers
  fields as CFDRMDF0_0
{0xE2C+0x4C*i} CFDRMDF{i}_8_3 (i=24..31) ro — RX Message Buffer Data Field 8 Registers
  fields as CFDRMDF0_0
{0xE30+0x4C*i} CFDRMDF{i}_9_3 (i=24..31) ro — RX Message Buffer Data Field 9 Registers
  fields as CFDRMDF0_0
{0xE34+0x4C*i} CFDRMDF{i}_10_3 (i=24..31) ro — RX Message Buffer Data Field 10 Registers
  fields as CFDRMDF0_0
{0xE38+0x4C*i} CFDRMDF{i}_11_3 (i=24..31) ro — RX Message Buffer Data Field 11 Registers
  fields as CFDRMDF0_0
{0xE3C+0x4C*i} CFDRMDF{i}_12_3 (i=24..31) ro — RX Message Buffer Data Field 12 Registers
  fields as CFDRMDF0_0
{0xE40+0x4C*i} CFDRMDF{i}_13_3 (i=24..31) ro — RX Message Buffer Data Field 13 Registers
  fields as CFDRMDF0_0
{0xE44+0x4C*i} CFDRMDF{i}_14_3 (i=24..31) ro — RX Message Buffer Data Field 14 Registers
  fields as CFDRMDF0_0
{0xE48+0x4C*i} CFDRMDF{i}_15_3 (i=24..31) ro — RX Message Buffer Data Field 15 Registers
  fields as CFDRMDF0_0
